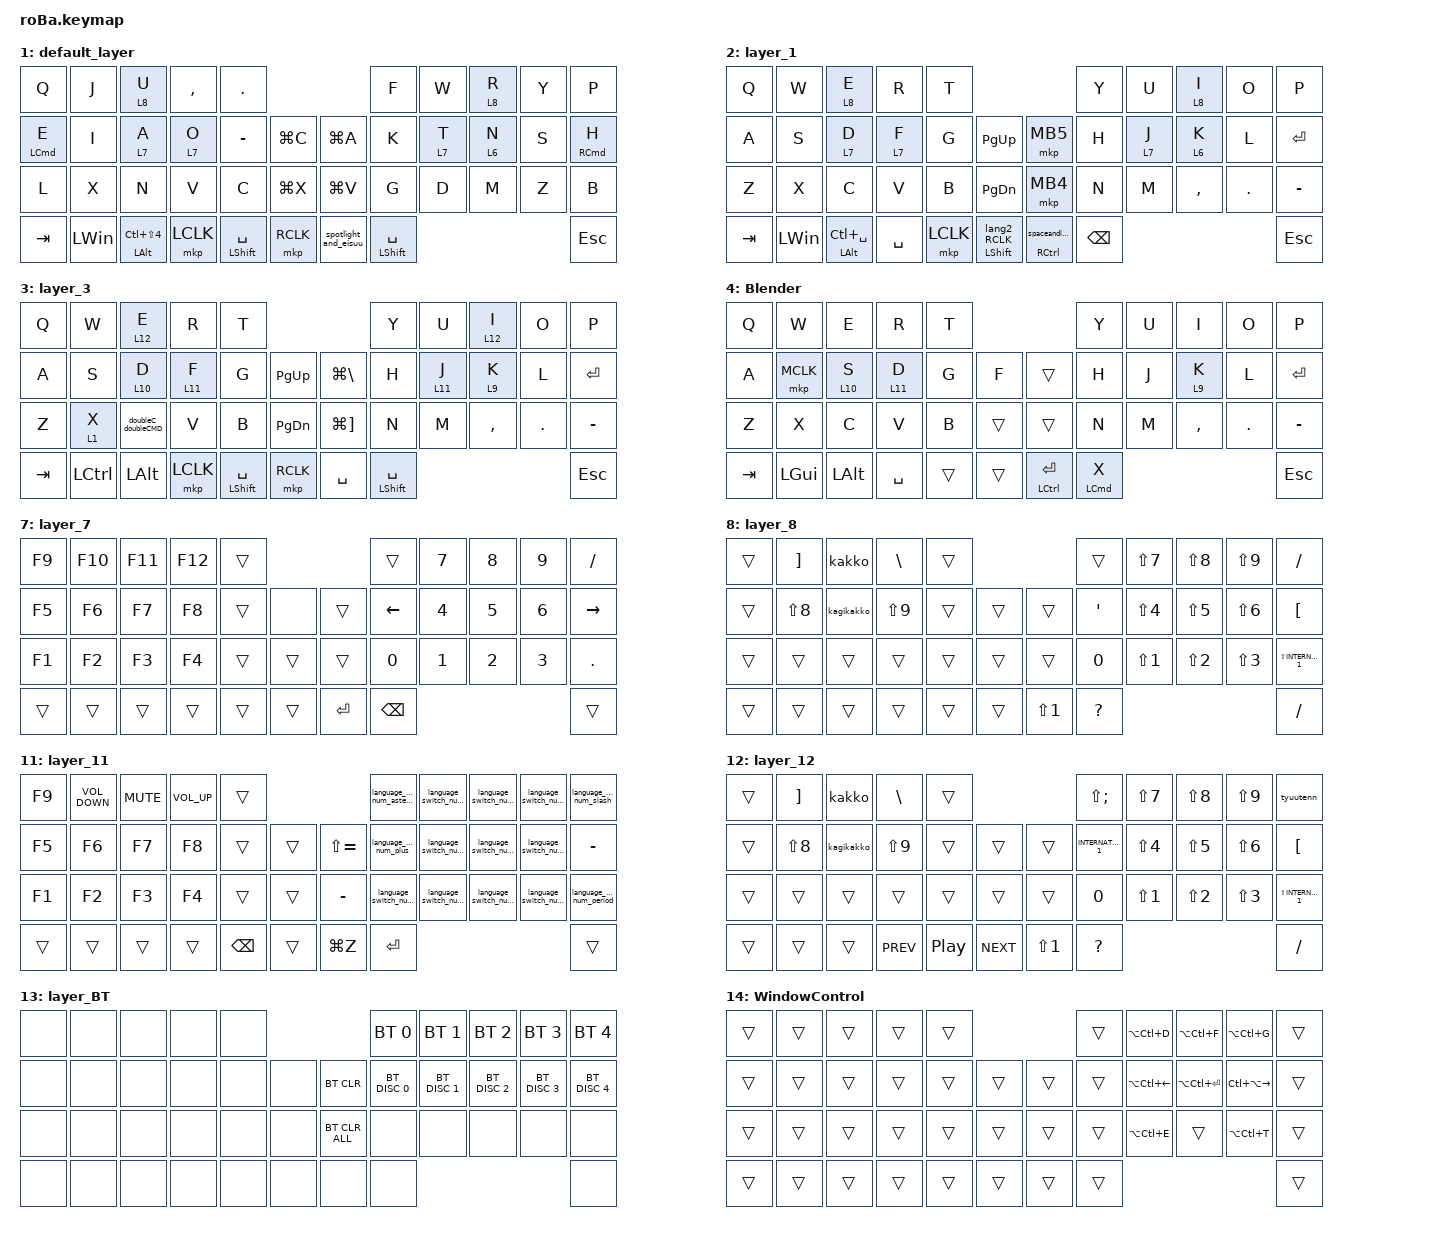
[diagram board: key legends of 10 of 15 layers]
#include <behaviors.dtsi>
#include <dt-bindings/zmk/bt.h>
#include <dt-bindings/zmk/keys.h>
#include <dt-bindings/zmk/pointing.h>

&mt {
    flavor = "balanced";
    quick-tap-ms = <0>;
};

&trackball {
    scroll-layers = <5 9>;

    // レイヤー6: 仮想デスクトップ系＋タスクビュー＋普通の右矢印

    layer6_ctrl {
        layers = <6>;
        bindings =
            <&kp LG(LA(LC(RIGHT_ARROW)))>,
            // 右: Win + Alt + Ctrl + →,,,,,,,,,,,,,,,,,,,,,,,,,,,,,,,
            <&kp LG(LA(LC(LEFT_ARROW)))>,
            // 左: Win + Alt + Ctrl + ←,,,,,,,,,,,,,,,,,,,,,,,,,,,,,,,
            <&kp LG(TAB)>,
            // 上: Win + Tab,,,,,,,,,,,,,,,,,,,,,,,,,,,,,,,
            <&kp LG(M)>;

        // 下: → だけ

        tick = <150>;
        wait-ms = <40>;
        tap-ms = <5>;
    };

    // レイヤー5: ウィンドウスナップ系

    layer5_snap {
        layers = <7>;
        bindings =
            <&kp LG(RIGHT_ARROW)>,
            // 右にスナップ (Win + →),,,,,,,,,,,,,,,,,,,,,,,,,,,,,,,
            <&kp LG(LEFT_ARROW)>,
            // 左にスナップ (Win + ←),,,,,,,,,,,,,,,,,,,,,,,,,,,,,,,
            <&kp LG(UP_ARROW)>,
            // 最大化   (Win + ↑),,,,,,,,,,,,,,,,,,,,,,,,,,,,,,,
            <&kp LG(DOWN_ARROW)>;

        // 最小化 or 元のサイズ (Win + ↓)

        tick = <150>;
        wait-ms = <40>;
        tap-ms = <5>;
    };

    // レイヤー13: ウィンドウ管理と特殊ショートカット

    layer13_window_ctrl {
        layers = <11>;
        bindings =
            <&kp LC(LA(RIGHT))>,
            // 右：ウィンドウを右半分に (Ctrl + Cmd + →),,,,,,,,,,,,,,,,,,,,,,,,
            <&kp LC(LA(LEFT))>,
            // 左：ウィンドウを左半分に (Ctrl + Cmd + ←),,,,,,,,,,,,,,,,,,,,,,,,
            <&kp LA(LC(ENTER))>,
            // 上：Enter + Option + Command,,,,,,,,,,,,,,,,,,,,,,,,
            <&kp LG(W)>;

        // 下：アプリのウィンドウを閉じる (Cmd + W)

        tick = <150>;
        wait-ms = <40>;
        tap-ms = <5>;
    };

    // レイヤー12: macOSナビゲーション (Mission Control / Expose / Desktop)

    layer12_macos_nav {
        layers = <10>;
        bindings =
            <&kp LC(LEFT)>,
            // 右：右の仮想デスクトップへ移動 (Ctrl + →),,,,,,,,,,,,,,,,,,,,,,,,
            <&kp LC(RIGHT)>,
            // 左：左の仮想デスクトップへ移動 (Ctrl + ←),,,,,,,,,,,,,,,,,,,,,,,,
            <&kp LC(UP)>,
            // 上：ミッションコントロール (Ctrl + ↑),,,,,,,,,,,,,,,,,,,,,,,,
            <&kp LG(M)>;

        // 下：アプリケーションエクスポーズ (Ctrl + ↓)

        tick = <150>;        // 連続入力を防ぐため、少し余裕を持たせた設定
        wait-ms = <40>;
        tap-ms = <5>;
    };
};

/ {
    combos {
        compatible = "zmk,combos";

        tab {
            bindings = <&mkp MB5>;
            key-positions = <19 32>;
            layers = <1 2>;
        };

        shift_tab {
            bindings = <&mkp MB4>;
            key-positions = <19 30>;
            layers = <1 2>;
        };

        muhennkann {
            bindings = <&mkp MB3>;
            key-positions = <18 20>;
        };

        double_quotation {
            bindings = <&mkp MB1>;
            key-positions = <18 19 37>;
        };

        eq {
            bindings = <&mkp MB2>;
            key-positions = <19 20>;
        };

        goodnote {
            bindings = <&to 2>;
            key-positions = <15 16>;
        };

        onisi {
            bindings = <&to 1>;
            key-positions = <28 27>;
        };

        Mac {
            bindings = <&to 0>;
            key-positions = <0 9>;
        };

        macqwerty {
            bindings = <&to 3>;
            key-positions = <42 34>;
        };

        back {
            bindings = <&kp LG(RIGHT_BRACKET)>;
            key-positions = <19 30>;
            layers = <0 3>;
        };

        go {
            bindings = <&kp LG(BACKSLASH)>;
            key-positions = <19 32>;
            layers = <0 3>;
        };

        to_blender {
            bindings = <&to 4>;
            key-positions = <9 34>;
            layers = <1 2 0 3>;
        };

        todefalt {
            bindings = <&to 0>;
            key-positions = <0 42>;
        };

        BootLoader {
            bindings = <&mo 13>;
            key-positions = <4 26>;
        };

        quitApp {
            bindings = <&kp LG(Q)>;
            key-positions = <18 19 20 21>;
            layers = <0>;
        };
    };

    macros {
        // --- 既存のマクロ（維持） ---

        to_layer_0: to_layer_0 {
            compatible = "zmk,behavior-macro-one-param";
            #binding-cells = <1>;
            bindings = <&to 1 &macro_param_1to1 &kp MACRO_PLACEHOLDER>;
            label = "TO_LAYER_0";
        };

        taskview: taskview {
            compatible = "zmk,behavior-macro";
            #binding-cells = <0>;
            bindings = <&kp LG(TAB)>, <&macro_pause_for_release>, <&mkp LCLK>;

            label = "TASKVIEW";
        };

        kakko: kakko {
            compatible = "zmk,behavior-macro";
            #binding-cells = <0>;
            bindings =
                <&kp LANGUAGE_1 &kp RIGHT_BRACKET>,
                <&macro_wait_time 15>,
                <&kp BACKSLASH>,
                <&macro_wait_time 15>,
                <&kp ENTER &kp LEFT>;

            label = "KAKKO";
        };

        kagikakko: kagikakko {
            compatible = "zmk,behavior-macro";
            #binding-cells = <0>;
            bindings =
                <&kp LANGUAGE_2>,
                <&macro_wait_time 15>,
                <&kp LS(N8)>,
                <&macro_wait_time 15>,
                <&kp LS(N9)>,
                <&macro_wait_time 15>,
                <&kp LANGUAGE_1 &kp LEFT>;

            label = "KAGIKAKKO";
        };

        numlayer: numlayer {
            compatible = "zmk,behavior-macro";
            #binding-cells = <0>;
            bindings = <&kp LANGUAGE_2 &mo 7>;
            label = "NUMLAYER";
        };

        doubleenter: doubleenter {
            compatible = "zmk,behavior-macro";
            #binding-cells = <0>;
            bindings = <&kp ENTER>, <&macro_wait_time 10>, <&kp ENTER>;

            label = "DOUBLEENTER";
        };

        spotlight_search: spotlight_search {
            compatible = "zmk,behavior-macro";
            #binding-cells = <0>;
            bindings = <&kp LANGUAGE_2>, <&macro_wait_time 50>, <&kp LG(SPACE)>;

            label = "SPOTLIGHT_SEARCH";
        };

        new_space: new_space {
            compatible = "zmk,behavior-macro";
            #binding-cells = <0>;
            bindings = <&kp LC(NUMBER_1)>, <&macro_wait_time 1000>, <&mkp LCLK>;

            label = "NEW_SPACE";
        };

        newchat: newchat {
            compatible = "zmk,behavior-macro";
            #binding-cells = <0>;
            bindings = <&mkp LCLK>, <&macro_wait_time 500>, <&kp LS(LG(O))>;

            label = "NEWCHAT";
        };

        doubleCTRL: doubleCMD {
            compatible = "zmk,behavior-macro";
            #binding-cells = <0>;
            bindings = <&kp LCTRL>, <&macro_wait_time 15>, <&kp LCTRL>;

            label = "DOUBLECMD";
        };

        // --- 今回追加・JIS完全修正済み ---

        m_list: m_list {
            compatible = "zmk,behavior-macro";
            #binding-cells = <0>;
            wait-ms = <15>;
            tap-ms = <15>;
            bindings = <&kp LANG2 &kp MINUS &kp SPACE &kp LANG1>;
        };

        m_quote: m_quote {
            compatible = "zmk,behavior-macro";
            #binding-cells = <0>;
            wait-ms = <15>;
            tap-ms = <15>;
            bindings = <&kp LANG2 &kp LS(DOT) &kp SPACE &kp LANG1>; // JISで >
        };

        m_todo: m_todo {
            compatible = "zmk,behavior-macro";
            #binding-cells = <0>;
            wait-ms = <15>;
            tap-ms = <15>;
            bindings = <&kp LANG2 &kp MINUS &kp SPACE &kp AT_SIGN &kp LEFT_BRACKET &kp SPACE &kp LANG1>; // JISで [ ]
        };

        m_tag: m_tag {
            compatible = "zmk,behavior-macro";
            #binding-cells = <0>;
            wait-ms = <15>;
            tap-ms = <15>;
            bindings = <&kp LANG2 &kp LS(N3) &kp LANG1>; // JISで #
        };

        m_task_tag: m_task_tag {
            compatible = "zmk,behavior-macro";
            #binding-cells = <0>;
            wait-ms = <15>;
            tap-ms = <15>;
            bindings = <&kp LANG2 &kp MINUS &kp SPACE &kp AT_SIGN &kp LEFT_BRACKET &kp SPACE &kp LS(N3) &kp LANG1>;
        };

        m_h2: m_h2 {
            compatible = "zmk,behavior-macro";
            #binding-cells = <0>;
            wait-ms = <15>;
            tap-ms = <15>;
            bindings = <&kp LANG2 &kp LS(N3) &kp LS(N3) &kp SPACE &kp LANG1>;
        };

        m_h3: m_h3 {
            compatible = "zmk,behavior-macro";
            #binding-cells = <0>;
            wait-ms = <15>;
            tap-ms = <15>;
            bindings = <&kp LANG2 &kp LS(N3) &kp LS(N3) &kp LS(N3) &kp SPACE &kp LANG1>;
        };

        m_bold: m_bold {
            compatible = "zmk,behavior-macro";
            #binding-cells = <0>;
            wait-ms = <15>;
            tap-ms = <15>;
            bindings = <&kp LANG2 &kp LS(COLON) &kp LS(COLON) &kp LS(COLON) &kp LS(COLON) &kp LEFT &kp LEFT &kp LANG1>; // JISで *
        };

        toMac: toMac {
            compatible = "zmk,behavior-macro";
            #binding-cells = <0>;
            bindings = <&bt BT_SEL 0>, <&macro_wait_time 200>, <&to 0>;

            label = "TOMAC";
        };

        toiPad: toiPad {
            compatible = "zmk,behavior-macro";
            #binding-cells = <0>;
            bindings = <&bt BT_SEL 1>, <&macro_wait_time 200>, <&to 0>;

            label = "TOIPAD";
        };

        toNum_and_lang2: toNum_and_lang2 {
            compatible = "zmk,behavior-macro";
            #binding-cells = <0>;
            bindings = <&kp LANGUAGE_2>, <&macro_wait_time 50>, <&to 8>;

            label = "TONUM_AND_LANG2";
        };

        BackToNum_and_lang1_at_2: BackToNum_and_lang1 {
            compatible = "zmk,behavior-macro";
            #binding-cells = <0>;
            bindings = <&kp LANGUAGE_1>, <&macro_wait_time 50>, <&to 0>;

            label = "BACKTONUM_AND_LANG1";
        };

        BackToNum_and_lang1_at_3: BackToNum_and_lang1_at_3 {
            compatible = "zmk,behavior-macro";
            #binding-cells = <0>;
            bindings = <&kp LANGUAGE_1>, <&macro_wait_time 50>, <&to 3>;

            label = "BACKTONUM_AND_LANG1_AT_3";
        };

        new_mac: new_mac {
            compatible = "zmk,behavior-macro";
            #binding-cells = <0>;
            bindings =
                <&kp LANGUAGE_2 &to 11>,
                <&macro_pause_for_release>,
                <&kp LANGUAGE_1 &to 0>;

            label = "NEW_MAC";
        };

        new_m: new_m {
            compatible = "zmk,behavior-macro";
            #binding-cells = <0>;
            bindings =
                <&kp LANGUAGE_2 &to 11>,
                <&macro_pause_for_release>,
                <&kp LANGUAGE_1 &to 3>;

            label = "NEW_M";
        };

        language_switch_num_0: language_switch_num_0 {
            compatible = "zmk,behavior-macro";
            #binding-cells = <0>;
            bindings =
                <&kp LANGUAGE_2>,
                <&macro_wait_time 15>,
                <&kp N0>,
                <&macro_wait_time 15>,
                <&kp LANGUAGE_1>;

            label = "LANGUAGE_SWITCH_NUM_0";
        };

        language_switch_num_1: language_switch_num_1 {
            compatible = "zmk,behavior-macro";
            #binding-cells = <0>;
            bindings =
                <&kp LANGUAGE_2>,
                <&macro_wait_time 2>,
                <&kp N1>,
                <&macro_wait_time 2>,
                <&kp LANGUAGE_1>;

            label = "LANGUAGE_SWITCH_NUM_1";
        };

        language_switch_num_2: language_switch_num_2 {
            compatible = "zmk,behavior-macro";
            #binding-cells = <0>;
            bindings =
                <&kp LANGUAGE_2>,
                <&macro_wait_time 15>,
                <&kp N2>,
                <&macro_wait_time 15>,
                <&kp LANGUAGE_1>;

            label = "LANGUAGE_SWITCH_NUM_2";
        };

        language_switch_num_3: language_switch_num_3 {
            compatible = "zmk,behavior-macro";
            #binding-cells = <0>;
            bindings =
                <&kp LANGUAGE_2>,
                <&macro_wait_time 15>,
                <&kp N3>,
                <&macro_wait_time 15>,
                <&kp LANGUAGE_1>;

            label = "LANGUAGE_SWITCH_NUM_3";
        };

        language_switch_num_4: language_switch_num_4 {
            compatible = "zmk,behavior-macro";
            #binding-cells = <0>;
            bindings =
                <&kp LANGUAGE_2>,
                <&macro_wait_time 15>,
                <&kp N4>,
                <&macro_wait_time 15>,
                <&kp LANGUAGE_1>;

            label = "LANGUAGE_SWITCH_NUM_4";
        };

        language_switch_num_5: language_switch_num_5 {
            compatible = "zmk,behavior-macro";
            #binding-cells = <0>;
            bindings =
                <&kp LANGUAGE_2>,
                <&macro_wait_time 15>,
                <&kp N5>,
                <&macro_wait_time 15>,
                <&kp LANGUAGE_1>;

            label = "LANGUAGE_SWITCH_NUM_5";
        };

        language_switch_num_6: language_switch_num_6 {
            compatible = "zmk,behavior-macro";
            #binding-cells = <0>;
            bindings =
                <&kp LANGUAGE_2>,
                <&macro_wait_time 15>,
                <&kp N6>,
                <&macro_wait_time 15>,
                <&kp LANGUAGE_1>;

            label = "LANGUAGE_SWITCH_NUM_6";
        };

        language_switch_num_7: language_switch_num_7 {
            compatible = "zmk,behavior-macro";
            #binding-cells = <0>;
            bindings =
                <&kp LANGUAGE_2>,
                <&macro_wait_time 15>,
                <&kp N7>,
                <&macro_wait_time 15>,
                <&kp LANGUAGE_1>;

            label = "LANGUAGE_SWITCH_NUM_7";
        };

        language_switch_num_8: language_switch_num_8 {
            compatible = "zmk,behavior-macro";
            #binding-cells = <0>;
            bindings =
                <&kp LANGUAGE_2>,
                <&macro_wait_time 15>,
                <&kp N8>,
                <&macro_wait_time 15>,
                <&kp LANGUAGE_1>;

            label = "LANGUAGE_SWITCH_NUM_8";
        };

        language_switch_num_9: language_switch_num_9 {
            compatible = "zmk,behavior-macro";
            #binding-cells = <0>;
            bindings =
                <&kp LANGUAGE_2>,
                <&macro_wait_time 15>,
                <&kp N9>,
                <&macro_wait_time 15>,
                <&kp LANGUAGE_1>;

            label = "LANGUAGE_SWITCH_NUM_9";
        };

        tyuutenn: tyuutenn {
            compatible = "zmk,behavior-macro";
            #binding-cells = <0>;
            bindings = <&kp LANGUAGE_1>, <&macro_wait_time 15>, <&kp SLASH>;

            label = "TYUUTENN";
        };

        language_switch_num_period: language_switch_num_period {
            compatible = "zmk,behavior-macro";
            #binding-cells = <0>;
            bindings =
                <&kp LANGUAGE_2>,
                <&macro_wait_time 15>,
                <&kp PERIOD>,
                <&macro_wait_time 15>,
                <&kp LANGUAGE_1>;

            label = "LANGUAGE_SWITCH_NUM_PERIOD";
        };

        language_switch_num_slash: language_switch_num_slash {
            compatible = "zmk,behavior-macro";
            #binding-cells = <0>;
            bindings =
                <&kp LANGUAGE_2>,
                <&macro_wait_time 15>,
                <&kp SLASH>,
                <&macro_wait_time 15>,
                <&kp LANGUAGE_1>;

            label = "LANGUAGE_SWITCH_NUM_SLASH";
        };

        language_switch_num_plus: language_switch_num_colon {
            compatible = "zmk,behavior-macro";
            #binding-cells = <0>;
            bindings =
                <&kp LANGUAGE_2>,
                <&macro_wait_time 15>,
                <&kp COLON>,
                <&macro_wait_time 15>,
                <&kp LANGUAGE_1>;

            label = "LANGUAGE_SWITCH_NUM_COLON";
        };

        language_switch_num_asterrisc: language_switch_num_asterrisc {
            compatible = "zmk,behavior-macro";
            #binding-cells = <0>;
            bindings =
                <&kp LANGUAGE_2>,
                <&macro_wait_time 3>,
                <&kp RS(COLON)>,
                <&macro_wait_time 15>,
                <&kp LANGUAGE_1>;

            label = "LANGUAGE_SWITCH_NUM_ASTERRISC";
        };

        language_switch_num_haihun: language_switch_num_haihun {
            compatible = "zmk,behavior-macro";
            #binding-cells = <0>;
            bindings =
                <&kp LANGUAGE_2>,
                <&macro_wait_time 15>,
                <&kp MINUS>,
                <&macro_wait_time 15>,
                <&kp LANGUAGE_1>;

            label = "LANGUAGE_SWITCH_NUM_HAIHUN";
        };

        spotlight_and_eisuu: spotlight_and_eisuu {
            compatible = "zmk,behavior-macro";
            #binding-cells = <0>;
            bindings = <&kp LANGUAGE_2>, <&macro_wait_time 10>, <&kp LG(SPACE)>;

            label = "SPOTLIGHT_AND_EISUU";
        };
    };

    behaviors {
        lt_to_layer_0: lt_to_layer_0 {
            compatible = "zmk,behavior-hold-tap";
            label = "LAYER_TAP_TO_0";
            bindings = <&mo>, <&to_layer_0>;

            #binding-cells = <2>;
            tapping-term-ms = <200>;
        };

        momkp: momkp {
            compatible = "zmk,behavior-hold-tap";
            label = "MOMKP";
            bindings = <&mo>, <&mkp>;

            #binding-cells = <2>;
            tapping-term-ms = <150>;
        };

        kpmkp: kpmkp {
            compatible = "zmk,behavior-hold-tap";
            label = "KPMKP";
            bindings = <&kp>, <&mkp>;

            #binding-cells = <2>;
            tapping-term-ms = <150>;
            flavor = "tap-preferred";
        };

        lang2_RCLK: lang2_RCLK {
            compatible = "zmk,behavior-tap-dance";
            label = "LANG2_RCLK";
            #binding-cells = <0>;
            bindings = <&mkp RCLK>, <&kp LANGUAGE_2>;

            tapping-term-ms = <350>;
        };

        new_behavior_none: new_behavior_none {
            compatible = "zmk,behavior-hold-tap";
            label = "NEW_BEHAVIOR_NONE";
            bindings = <&kp>, <&lang2_RCLK>;

            #binding-cells = <2>;
            tapping-term-ms = <150>;
        };

        tapdancespace: tapdancespace {
            compatible = "zmk,behavior-hold-tap";
            label = "TAPDANCESPACE";
            #binding-cells = <2>;
            tapping-term-ms = <200>;
            bindings = <&mo>, <&spaceandlang2>;
        };

        spaceandlang2: spaceandlang2 {
            compatible = "zmk,behavior-tap-dance";
            label = "SPACEANDLANG2";
            #binding-cells = <0>;
            bindings = <&kp ENTER>, <&kp LANG1>;

            tapping-term-ms = <350>;
        };

        tskview_kp: tskview_kp {
            compatible = "zmk,behavior-hold-tap";
            label = "TSKVIEW_KP";
            bindings = <&taskview>, <&kp>;

            #binding-cells = <2>;
            tapping-term-ms = <150>;
        };

        LT_Advance: LT_Advance {
            compatible = "zmk,behavior-hold-tap";
            label = "LT_ADVANCE";
            bindings = <&mo>, <&kp>;

            #binding-cells = <2>;
            tapping-term-ms = <150>;
            flavor = "tap-preferred";
        };

        MT_Advance: MT_Advance {
            compatible = "zmk,behavior-hold-tap";
            label = "MT_ADVANCE";
            bindings = <&kp>, <&kp>;

            #binding-cells = <2>;
            tapping-term-ms = <150>;
            flavor = "tap-preferred";
        };

        num_layer: num_layer {
            compatible = "zmk,behavior-hold-tap";
            label = "NUM_LAYER";
            bindings = <&numlayer>, <&kp>;

            #binding-cells = <2>;
            tapping-term-ms = <150>;
            flavor = "tap-preferred";
        };

        new_behavior: new_behavior {
            compatible = "zmk,behavior-hold-tap";
            label = "NEW_BEHAVIOR";
            bindings = <&kp>, <&lang2_RCLK>;

            #binding-cells = <2>;
            tapping-term-ms = <150>;
            flavor = "tap-preferred";
        };

        doubleneter: doubleneter {
            compatible = "zmk,behavior-tap-dance";
            label = "DOUBLENETER";
            #binding-cells = <0>;
            bindings = <&kp LC(C)>, <&doubleenter>;

            tapping-term-ms = <350>;
        };

        enterctrl: enterctrl {
            compatible = "zmk,behavior-hold-tap";
            label = "ENTERCTRL";
            bindings = <&kp>, <&spaceandlang2>;

            #binding-cells = <2>;
            tapping-term-ms = <150>;
            flavor = "tap-preferred";
        };

        space_newchat: space_newchat {
            compatible = "zmk,behavior-tap-dance";
            label = "SPACE_NEWCHAT";
            #binding-cells = <0>;
            tapping-term-ms = <350>;
            bindings = <&kp SPACE>, <&kp LS(LG(O))>, <&newchat>;
        };

        space_mo: space_mo {
            compatible = "zmk,behavior-hold-tap";
            label = "SPACE_MO";
            bindings = <&mo>, <&space_newchat>;

            #binding-cells = <2>;
            tapping-term-ms = <150>;
            flavor = "tap-preferred";
        };

        doubleN_doubleCMD: doubleN_doubleCMD {
            compatible = "zmk,behavior-tap-dance";
            label = "DOUBLEN_DOUBLECMD";
            #binding-cells = <0>;
            bindings = <&kp N>, <&doubleCTRL>;

            tapping-term-ms = <350>;
        };

        doubleC_doubleCMD: doubleC_doubleCMD {
            compatible = "zmk,behavior-tap-dance";
            label = "DOUBLEC_DOUBLECMD";
            #binding-cells = <0>;
            bindings = <&kp C>, <&doubleCTRL>;

            tapping-term-ms = <350>;
        };

        Num_back_to_2: Num_back_to_2 {
            compatible = "zmk,behavior-hold-tap";
            label = "NUM_BACK_TO_2";
            bindings = <&new_mac>, <&kp>;

            #binding-cells = <2>;
            tapping-term-ms = <150>;
            flavor = "tap-preferred";
        };

        Num_Back_to_3: Num_Back_to_3 {
            compatible = "zmk,behavior-hold-tap";
            label = "NUM_BACK_TO_3";
            bindings = <&new_m>, <&kp>;

            #binding-cells = <2>;
            tapping-term-ms = <150>;
            flavor = "tap-preferred";
        };

        Mkpkp: Mkpkp {
            compatible = "zmk,behavior-hold-tap";
            label = "MKPKP";
            bindings = <&mkp>, <&kp>;

            #binding-cells = <2>;
            tapping-term-ms = <150>;
        };
    };

    keymap {
        compatible = "zmk,keymap";

        layer_2 {
            bindings = <
&kp Q                       &kp J             &LT_Advance 12 U                        &kp COMMA         &kp DOT                                                            &kp F                         &kp W             &LT_Advance 12 R  &kp Y  &kp P
&MT_Advance LEFT_COMMAND E  &LT_Advance 14 I  &LT_Advance 10 A                        &LT_Advance 11 O  &kp MINUS                     &kp LG(C)      &kp LG(A)             &kp K                         &LT_Advance 11 T  &LT_Advance 9 N   &kp S  &MT_Advance RIGHT_COMMAND H
&kp L                       &kp X             &MT_Advance LEFT_SHIFT N                &Mkpkp MB3 V      &kp C                         &kp LG(X)      &kp LG(V)             &kp G                         &kp D             &kp M             &kp Z  &kp B
&kp TAB                     &kp LEFT_ALT      &MT_Advance LCTRL LS(LC(LG(NUMBER_4)))  &mkp LCLK         &MT_Advance LEFT_SHIFT SPACE  &mkp RCLK      &spotlight_and_eisuu  &MT_Advance LEFT_SHIFT SPACE                                             &kp ESC
            >;

            sensor-bindings = <&inc_dec_kp PG_UP PAGE_DOWN>;
        };

        default_layer {
            bindings = <
&kp Q                       &kp J         &LT_Advance 8 U                &kp COMMA        &kp DOT                                                            &kp F                         &kp W            &LT_Advance 8 R  &kp Y  &kp P
&MT_Advance LEFT_COMMAND E  &kp I         &LT_Advance 7 A                &LT_Advance 7 O  &kp MINUS                     &kp LG(C)      &kp LG(A)             &kp K                         &LT_Advance 7 T  &LT_Advance 6 N  &kp S  &MT_Advance RIGHT_COMMAND H
&kp L                       &kp X         &kp N                          &kp V            &kp C                         &kp LG(X)      &kp LG(V)             &kp G                         &kp D            &kp M            &kp Z  &kp B
&kp TAB                     &kp LEFT_WIN  &mt LEFT_ALT LC(LS(NUMBER_4))  &mkp LCLK        &MT_Advance LEFT_SHIFT SPACE  &mkp RCLK      &spotlight_and_eisuu  &MT_Advance LEFT_SHIFT SPACE                                           &kp ESC
            >;

            sensor-bindings = <&inc_dec_kp PG_UP PAGE_DOWN>;
        };

        layer_1 {
            bindings = <
&kp Q    &kp W         &LT_Advance 8 E         &kp R            &kp T                                                               &kp Y     &kp U            &LT_Advance 8 I  &kp O    &kp P
&kp A    &kp S         &LT_Advance 7 D         &LT_Advance 7 F  &kp G      &kp PG_UP                            &mkp MB5            &kp H     &LT_Advance 7 J  &LT_Advance 6 K  &kp L    &kp ENTER
&kp Z    &kp X         &kp C                   &kp V            &kp B      &kp PAGE_DOWN                        &mkp MB4            &kp N     &kp M            &kp COMMA        &kp DOT  &kp MINUS
&kp TAB  &kp LEFT_WIN  &mt LEFT_ALT LC(SPACE)  &kp SPACE        &mkp LCLK  &new_behavior_none LEFT_SHIFT 0      &enterctrl RCTRL 0  &kp BSPC                                             &kp ESC
            >;

            sensor-bindings = <&inc_dec_kp PG_UP PAGE_DOWN>;
        };

        layer_3 {
            bindings = <
&kp Q    &kp W      &LT_Advance 12 E    &kp R             &kp T                                                                   &kp Y                         &kp U             &LT_Advance 12 I  &kp O    &kp P
&kp A    &kp S      &LT_Advance 10 D    &LT_Advance 11 F  &kp G                         &kp PG_UP          &kp LG(BACKSLASH)      &kp H                         &LT_Advance 11 J  &LT_Advance 9 K   &kp L    &kp ENTER
&kp Z    &lt 1 X    &doubleC_doubleCMD  &kp V             &kp B                         &kp PAGE_DOWN      &kp LG(RIGHT_BRACKET)  &kp N                         &kp M             &kp COMMA         &kp DOT  &kp MINUS
&kp TAB  &kp LCTRL  &kp LEFT_ALT        &mkp LCLK         &MT_Advance LEFT_SHIFT SPACE  &mkp RCLK          &kp SPACE              &MT_Advance LEFT_SHIFT SPACE                                               &kp ESC
            >;

            sensor-bindings = <&inc_dec_kp PG_UP PAGE_DOWN>;
        };

        Blender {
            bindings = <
&kp Q    &kp W      &kp E             &kp R      &kp T                                &kp Y               &kp U  &kp I      &kp O    &kp P
&kp A    &mkp MCLK  &LT_Advance 10 S  &lt 11 D   &kp G   &kp F       &trans           &kp H               &kp J  &lt 9 K    &kp L    &kp RET
&kp Z    &kp X      &kp C             &kp V      &kp B   &trans      &trans           &kp N               &kp M  &kp COMMA  &kp DOT  &kp MINUS
&kp TAB  &kp LGUI   &kp LALT          &kp SPACE  &trans  &trans      &mt LCTRL ENTER  &mt LEFT_COMMAND X                             &kp ESC
            >;
        };

        layer_9 {
            bindings = <
&bt BT_SEL 0          &bt BT_SEL 0      &bt BT_SEL 1       &bt BT_SEL 2       &bt BT_SEL 3                                  &none      &none     &none   &none     &none
&kp LA(LC(LS(LEFT)))  &bt BT_DISC 0     &bt BT_DISC 1      &bt BT_DISC 2      &kp LS(LA(LC(RIGHT)))  &none       &none      &none      &mkp MB1  &trans  &mkp MB2  &none
&kp LG(UP_ARROW)      &kp LG(LS(LEFT))  &kp LG(LC(LA(Q)))  &kp LS(LG(RIGHT))  &kp LS(LG(S))          &none       &none      &none      &mkp MB4  &none   &mkp MB5  &none
&trans                &trans            &trans             &trans             &trans                 &trans      &kp RC(C)  &kp RC(V)                              &none
            >;
        };

        layer_6 {
            bindings = <
&bt BT_SEL 0          &bt BT_SEL 1      &bt BT_SEL 2       &bt BT_SEL 3       &bt BT_SEL 4                                  &none       &kp HOME         &kp UP     &kp END      &none
&kp LA(LC(LS(LEFT)))  &kp LG(LEFT)      &mo 7              &kp LG(RIGHT)      &kp LS(LA(LC(RIGHT)))  &kp T       &none      &kp LC(A)   &kp LEFT         &kp DOWN   &kp RIGHT    &kp LA(F4)
&kp LG(UP_ARROW)      &kp LG(LS(LEFT))  &kp LG(LC(LA(Q)))  &kp LS(LG(RIGHT))  &kp LS(LG(S))          &kp T       &kp LC(A)  &kp LC(A)   &kp LC(LS(TAB))  &kp LC(T)  &kp LC(TAB)  &kp LC(W)
&trans                &trans            &trans             &trans             &trans                 &trans      &kp ENTER  &kp DELETE                                           &none
            >;
        };

        layer_7 {
            bindings = <
&kp F9  &kp F10  &kp F11  &kp F12  &trans                         &trans    &kp N7  &kp N8  &kp N9  &kp FSLH
&kp F5  &kp F6   &kp F7   &kp F8   &trans  &none       &trans     &kp LEFT  &kp N4  &kp N5  &kp N6  &kp RIGHT
&kp F1  &kp F2   &kp F3   &kp F4   &trans  &trans      &trans     &kp N0    &kp N1  &kp N2  &kp N3  &kp DOT
&trans  &trans   &trans   &trans   &trans  &trans      &kp ENTER  &kp BSPC                          &trans
            >;
        };

        layer_8 {
            bindings = <
&trans  &kp RBKT    &kakko      &kp BSLH    &trans                                &trans            &kp LS(N7)  &kp LS(N8)  &kp LS(N9)  &kp SLASH
&trans  &kp LS(N8)  &kagikakko  &kp LS(N9)  &trans  &trans      &trans            &kp SINGLE_QUOTE  &kp LS(N4)  &kp LS(N5)  &kp LS(N6)  &kp LEFT_BRACKET
&trans  &trans      &trans      &trans      &trans  &trans      &trans            &kp N0            &kp LS(N1)  &kp LS(N2)  &kp LS(N3)  &kp LS(INTERNATIONAL_1)
&trans  &trans      &trans      &trans      &trans  &trans      &kp LS(NUMBER_1)  &kp QUESTION                                          &kp FSLH
            >;
        };

        layer_13 {
            bindings = <
&toMac            &kp LC(N1)     &kp LC(N2)     &kp LC(N3)     &toiPad                                                  &none      &none     &none   &none     &none
&bt BT_SEL 2      &kp LC(N4)     &kp LC(N5)     &kp LC(N6)     &kp LG(LS(LC(NUMBER_4)))  &trans              &none      &none      &mkp MB1  &trans  &mkp MB2  &none
&kp LG(UP_ARROW)  &bt BT_DISC 0  &bt BT_DISC 1  &bt BT_DISC 2  &kp LS(LG(S))             &none               &none      &none      &mkp MB4  &none   &mkp MB5  &none
&trans            &trans         &trans         &trans         &kp LANGUAGE_2            &kp LANGUAGE_2      &kp LG(C)  &kp LG(V)                              &none
            >;
        };

        layer_10 {
            bindings = <
&bt BT_SEL 0          &bt BT_SEL 1      &bt BT_SEL 2       &bt BT_SEL 3       &bt BT_SEL 4                                              &none           &kp HOME         &kp UP     &kp END      &none
&kp LA(LC(LS(LEFT)))  &kp LG(LEFT)      &mo 10             &kp LG(RIGHT)      &kp LS(LA(LC(RIGHT)))  &kp T       &kp LS(LA(LC(LG(R))))  &kp LC(LEFT)    &kp LEFT         &kp DOWN   &kp RIGHT    &kp LC(RIGHT)
&kp LG(UP_ARROW)      &kp LG(LS(LEFT))  &kp LG(LC(LA(Q)))  &kp LS(LG(RIGHT))  &kp LS(LG(S))          &kp T       &kp LC(LA(LS(LG(F))))  &kp LC(A)       &kp LC(LS(TAB))  &kp LG(T)  &kp LC(TAB)  &kp LG(W)
&trans                &trans            &trans             &trans             &trans                 &trans      &trans                 &kp LANGUAGE_1                                           &none
            >;
        };

        layer_11 {
            bindings = <
&kp F9  &kp C_VOLUME_DOWN  &kp C_MUTE  &kp C_VOLUME_UP  &trans                                    &language_switch_num_asterrisc  &language_switch_num_7  &language_switch_num_8  &language_switch_num_9  &language_switch_num_slash
&kp F5  &kp F6             &kp F7      &kp F8           &trans         &trans      &kp LS(EQUAL)  &language_switch_num_plus       &language_switch_num_4  &language_switch_num_5  &language_switch_num_6  &kp MINUS
&kp F1  &kp F2             &kp F3      &kp F4           &trans         &trans      &kp MINUS      &language_switch_num_0          &language_switch_num_1  &language_switch_num_2  &language_switch_num_3  &language_switch_num_period
&trans  &trans             &trans      &trans           &kp BACKSPACE  &trans      &kp LG(Z)      &kp ENTER                                                                                               &trans
            >;
        };

        layer_12 {
            bindings = <
&trans  &kp RBKT    &kakko      &kp BSLH    &trans                                      &kp LS(SEMICOLON)    &kp LS(N7)  &kp LS(N8)  &kp LS(N9)  &tyuutenn
&trans  &kp LS(N8)  &kagikakko  &kp LS(N9)  &trans    &trans          &trans            &kp INTERNATIONAL_1  &kp LS(N4)  &kp LS(N5)  &kp LS(N6)  &kp LEFT_BRACKET
&trans  &trans      &trans      &trans      &trans    &trans          &trans            &kp N0               &kp LS(N1)  &kp LS(N2)  &kp LS(N3)  &kp LS(INTERNATIONAL_1)
&trans  &trans      &trans      &kp C_PREV  &kp C_PP  &kp C_NEXT      &kp LS(NUMBER_1)  &kp QUESTION                                             &kp FSLH
            >;
        };

        layer_BT {
            bindings = <
&none  &none  &none  &none  &none                             &bt BT_SEL 0   &bt BT_SEL 1   &bt BT_SEL 2   &bt BT_SEL 3   &bt BT_SEL 4
&none  &none  &none  &none  &none  &none      &bt BT_CLR      &bt BT_DISC 0  &bt BT_DISC 1  &bt BT_DISC 2  &bt BT_DISC 3  &bt BT_DISC 4
&none  &none  &none  &none  &none  &none      &bt BT_CLR_ALL  &none          &none          &none          &none          &none
&none  &none  &none  &none  &none  &none      &none           &none                                                       &none
            >;
        };

        WindowControl {
            bindings = <
&trans  &trans  &trans  &trans  &trans                      &trans  &kp LA(LC(D))     &kp LA(LC(F))      &kp LA(LC(G))      &trans
&trans  &trans  &trans  &trans  &trans  &trans      &trans  &trans  &kp LA(LC(LEFT))  &kp LA(LC(ENTER))  &kp LC(LA(RIGHT))  &trans
&trans  &trans  &trans  &trans  &trans  &trans      &trans  &trans  &kp LA(LC(E))     &trans             &kp LA(LC(T))      &trans
&trans  &trans  &trans  &trans  &trans  &trans      &trans  &trans                                                          &trans
            >;
        };
    };
};
